# R7FA4E10D register map
Vendor: Renesas Electronics Corporation; Series: RA4E1; File version: 1.20.00
CPU: CM33 r0p4, little endian, MPU, FPU, VTOR, 4 interrupt priority bits, 96 interrupts
Registers are 8-bit, read-write, reset 0x0 unless marked. A register's access mark holds for its fields unless they carry their own. Offsets are from the block's base; [hi:lo] are bit positions; 'fields as' and 'values as' point back to an identical list.

## FACI — Flash/CPU Interface
Base 0x407FE000
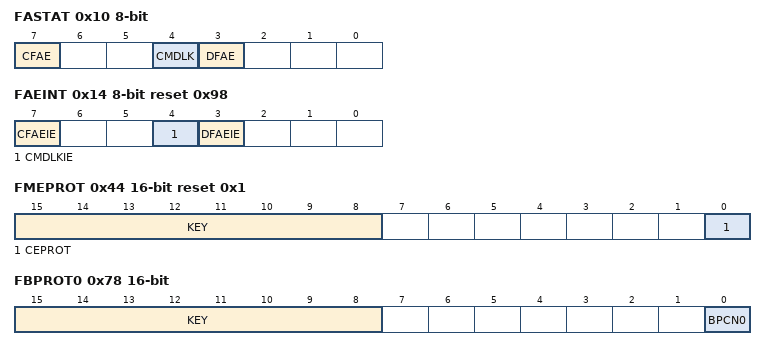
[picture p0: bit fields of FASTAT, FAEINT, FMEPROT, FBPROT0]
0x10 FASTAT — Flash Access Status Register
  [7] CFAE — Code Flash Memory Access Violation Flag
    0=No code flash memory access violation has occurred; 1=A code flash memory access violation has occurred
  [4] CMDLK ro — Command Lock Flag
    0=The flash sequencer is not in the command-locked state; 1=The flash sequencer is in the command-locked state
  [3] DFAE — Data Flash Memory Access Violation Flag
    0=No data flash memory access violation has occurred; 1=A data flash memory access violation has occurred
0x14 FAEINT reset 0x98 — Flash Access Error Interrupt Enable Register
  [7] CFAEIE — Code Flash Memory Access Violation Interrupt Enable
    0=Generation of an FIFERR interrupt request is disabled when FASTAT.CFAE is set to 1; 1=Generation of an FIFERR interrupt request is enabled when FASTAT.CFAE is set to 1
  [4] CMDLKIE — Command Lock Interrupt Enable
    0=Generation of an FIFERR interrupt request is disabled when FASTAT.CMDLK is set to 1; 1=Generation of an FIFERR interrupt request is enabled when FASTAT.CMDLK is set to 1
  [3] DFAEIE — Data Flash Memory Access Violation Interrupt Enable
    0=Generation of an FIFERR interrupt request is disabled when FASTAT.DFAE is set to 1; 1=Generation of an FIFERR interrupt request is enabled when FASTAT.DFAE is set to 1
0x18 FRDYIE — Flash Ready Interrupt Enable Register
  [0] FRDYIE — Flash Ready Interrupt Enable
    0=Generation of an FRDY interrupt request is disabled; 1=Generation of an FRDY interrupt request is enabled
0x30 FSADDR 32-bit — FACI Command Start Address Register
  [31:0] FSADDR — Start Address for FACI Command Processing
0x34 FEADDR 32-bit — FACI Command End Address Register
  [31:0] FEADDR — End Address for FACI Command Processing
0x44 FMEPROT 16-bit reset 0x1 — Flash P/E Mode Entry Protection Register
  [15:8] KEY wo — Key Code
  [0] CEPROT — Code Flash P/E Mode Entry Protection
    0=FENTRYC bit is not protected; 1=FENTRYC bit is protected
0x78 FBPROT0 16-bit — Flash Block Protection Register
  [15:8] KEY wo — Key Code
  [0] BPCN0 — Block Protection for Non-secure Cancel
    0=Block protection is enabled; 1=Block protection is disabled
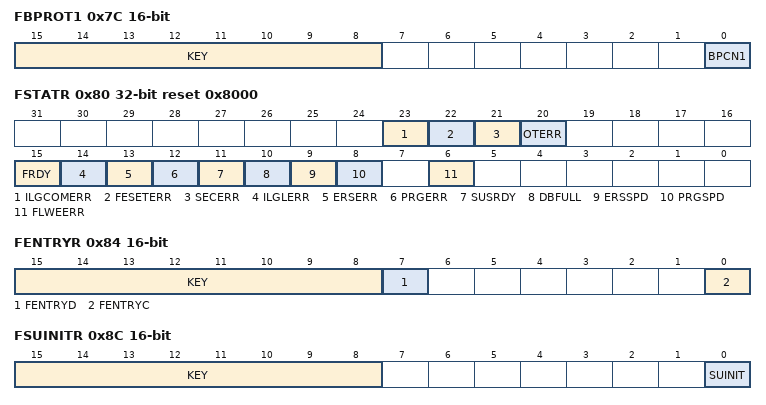
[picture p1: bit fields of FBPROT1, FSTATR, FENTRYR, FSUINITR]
0x7C FBPROT1 16-bit — Flash Block Protection for Secure Register
  [15:8] KEY wo — Key Code
  [0] BPCN1 — Block Protection for Secure Cancel
    values as FBPROT0.BPCN0
0x80 FSTATR 32-bit reset 0x8000 — Flash Status Register
  [23] ILGCOMERR ro — Illegal Command Error
    0=A status clear or forced stop command processing is complete; 1=An error has occurred
  [22] FESETERR ro — FENTRY Setting Error
    values as ILGCOMERR
  [21] SECERR ro — Security Error
    values as ILGCOMERR
  [20] OTERR ro — Other Error
    values as ILGCOMERR
  [15] FRDY ro — Flash Ready Flag
    0=Program, Block Erase, Multi Block Erase, P/E suspend, P/E resume, Forced Stop, Blank Check, or Configuration set command processing is in progress; 1=None of the above is in progress
  [14] ILGLERR ro — Illegal Command Error Flag
    0=The flash sequencer has not detected an illegal FACI command or illegal flash memory access; 1=The flash sequencer has detected an illegal FACI command or illegal flash memory access
  [13] ERSERR ro — Erasure Error Flag
    0=Erasure has completed successfully; 1=An error has occurred during erasure
  [12] PRGERR ro — Programming Error Flag
    0=Programming has completed successfully; 1=An error has occurred during programming
  [11] SUSRDY ro — Suspend Ready Flag
    0=The flash sequencer cannot receive P/E suspend commands; 1=The flash sequencer can receive P/E suspend commands
  [10] DBFULL ro — Data Buffer Full Flag
    0=The data buffer is empty; 1=The data buffer is full
  [9] ERSSPD ro — Erasure Suspend Status Flag
    0=The flash sequencer is not in the erasure suspension processing state or the erasure suspended state; 1=The flash sequencer is in the erasure suspension processing state or the erasure suspended state
  [8] PRGSPD ro — Programming Suspend Status Flag
    0=The flash sequencer is not in the programming suspension processing state or programming suspended state; 1=The flash sequencer is in the programming suspension processing state or programming suspended state
  [6] FLWEERR ro — Flash Write/Erase Protect Error Flag
    0=An error has not occurred; 1=An error has occurred
0x84 FENTRYR 16-bit — Flash P/E Mode Entry Register
  [15:8] KEY wo — Key Code
  [7] FENTRYD — Data Flash P/E Mode Entry
    0=Data flash is in read mode; 1=Data flash is in P/E mode
  [0] FENTRYC — Code Flash P/E Mode Entry
    0=Code flash is in read mode; 1=Code flash is in P/E mode
0x8C FSUINITR 16-bit — Flash Sequencer Setup Initialization Register
  [15:8] KEY wo — Key Code
  [0] SUINIT — Set-Up Initialization
    0=The FSADDR, FEADDR, FBPROT0, FBPROT1, FENTRYR, FBCCNT, and FCPSR flash sequencer setup registers keep their current values; 1=The FSADDR, FEADDR, FBPROT0, FBRPOT1, FENTRYR, FBCCNT, and FCPSR flash sequencer setup registers are initialized
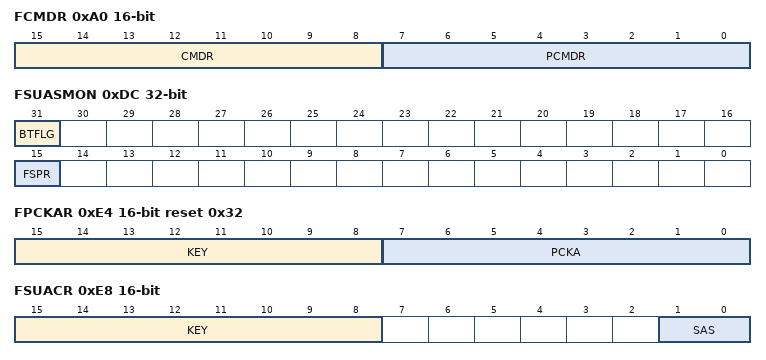
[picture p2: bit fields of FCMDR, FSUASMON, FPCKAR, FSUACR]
0xA0 FCMDR 16-bit ro — FACI Command Register
  [15:8] CMDR — Command Flag
  [7:0] PCMDR — Pre-command Flag
0xD0 FBCCNT — Blank Check Control Register
  [0] BCDIR — Blank Check Direction
    0=Blank checking is executed from the lower addresses to the higher addresses (incremental mode); 1=Blank checking is executed from the higher addresses to the lower addresses (decremental mode)
0xD4 FBCSTAT — Blank Check Status Register
  [0] BCST ro — Blank Check Status Flag
    0=The target area is in the non-programmed state, that is, the area has been erased but has not yet been reprogrammed; 1=The target area has been programmed with 0s or 1s
0xD8 FPSADDR 32-bit — Data Flash Programming Start Address Register
  [16:0] PSADR ro — Programmed Area Start Address
0xDC FSUASMON 32-bit ro (reset mask 0x7FFF7FFF) — Flash Startup Area Select Monitor Register
  [31] BTFLG — Flag of Startup Area Select for Boot Swap
    0=The startup area is the alternate block (block 1); 1=The startup area is the default block (block 0)
  [15] FSPR — Protection Programming Flag to set Boot Flag and Startup Area Control
    0=Protected state; 1=Non-protected state
0xE0 FCPSR 16-bit — Flash Sequencer Processing Switching Register
  [0] ESUSPMD — Erasure Suspend Mode
    0=Suspension priority mode; 1=Erasure priority mode
0xE4 FPCKAR 16-bit reset 0x32 — Flash Sequencer Processing Clock Notification Register
  [15:8] KEY wo — Key Code
  [7:0] PCKA — Flash Sequencer Operating Clock Notification
0xE8 FSUACR 16-bit — Flash Startup Area Control Register
  [15:8] KEY wo — Key Code
  [1:0] SAS — Startup Area Select
    0=Startup area is selected by BTFLG bit; 1=Startup area is selected by BTFLG bit; 2=Startup area is temporarily switched to the default area (block 0); 3=Startup area is temporarily switched to the alternate area (block 1)
